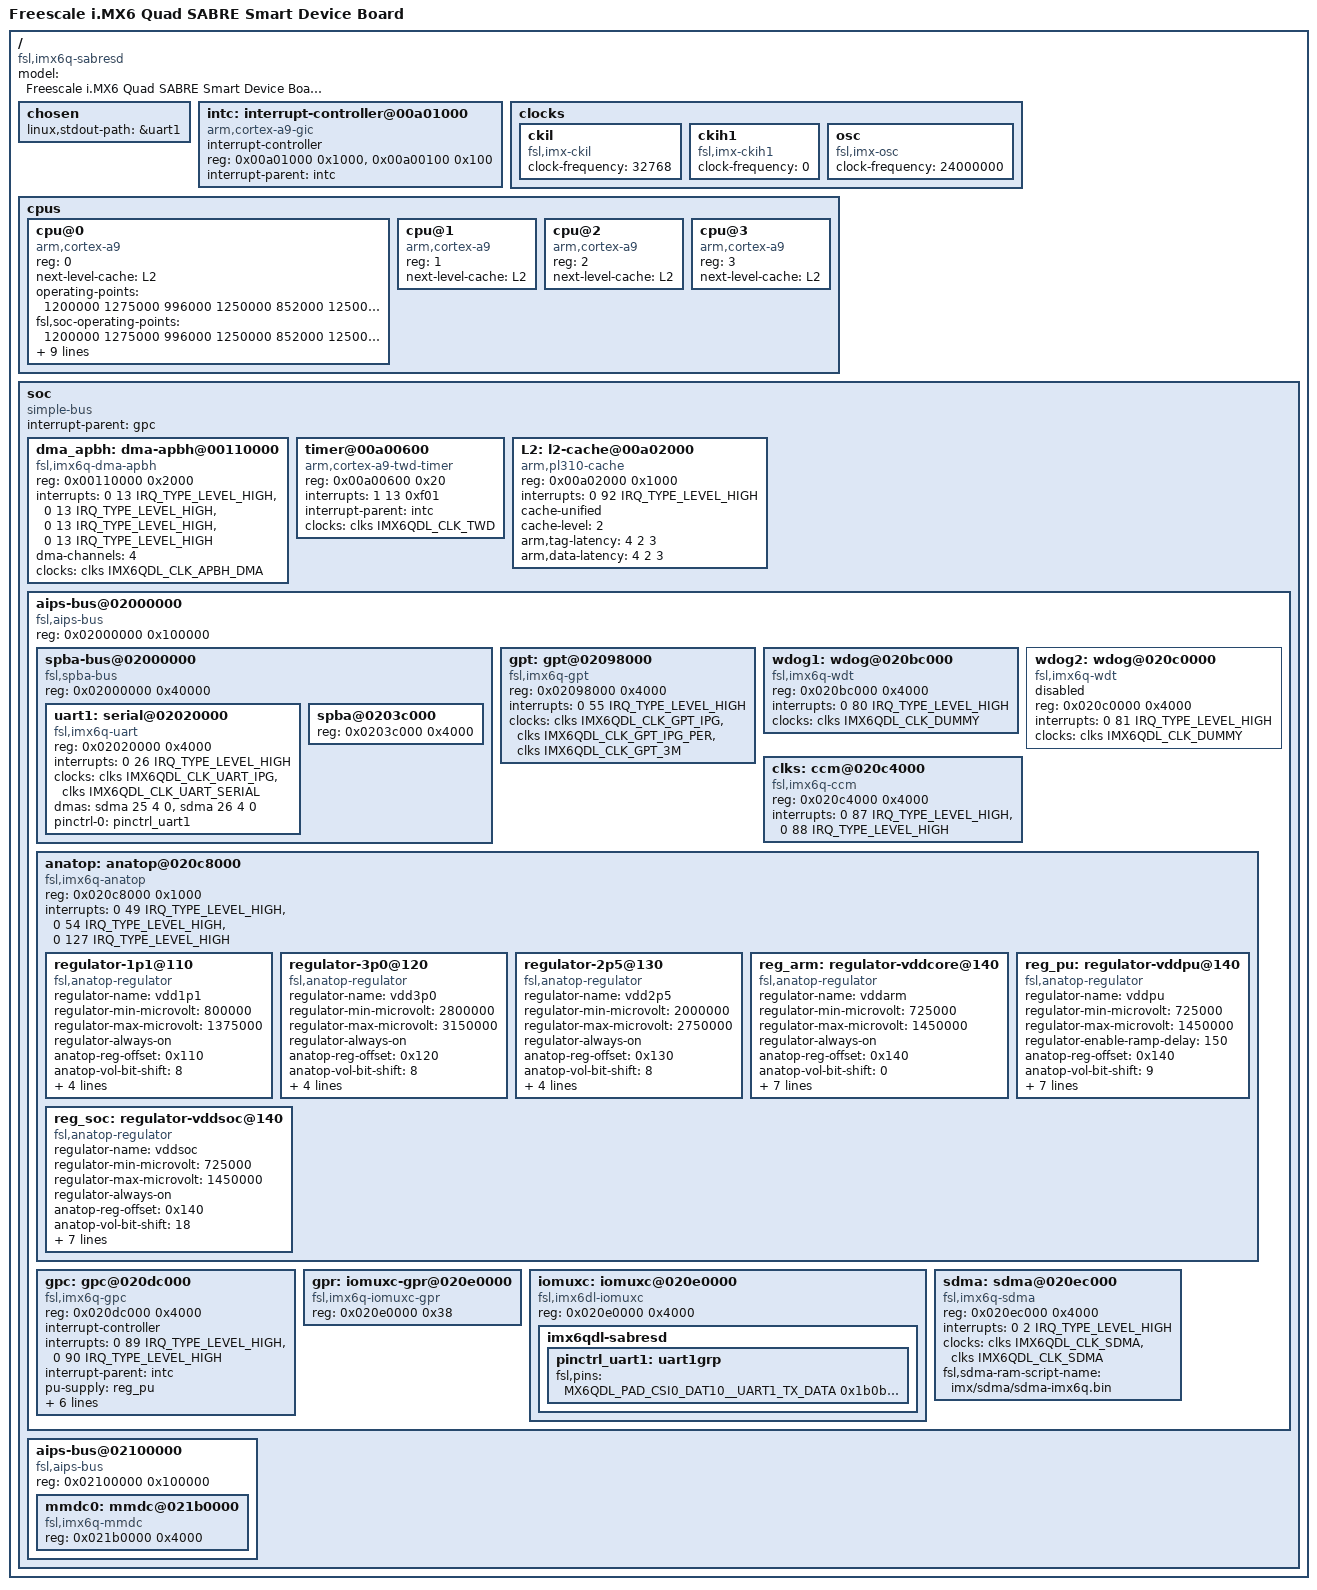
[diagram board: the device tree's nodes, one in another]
/*
* Copyright 2012 Freescale Semiconductor, Inc.
* Copyright 2011 Linaro Ltd.
*
* The code contained herein is licensed under the GNU General Public
* License. You may obtain a copy of the GNU General Public License
* Version 2 or later at the following locations:
*
* http://www.opensource.org/licenses/gpl-license.html
* http://www.gnu.org/copyleft/gpl.html
*/

/dts-v1/;

#include <dt-bindings/gpio/gpio.h>
#include <dt-bindings/input/input.h>
#include <dt-bindings/clock/imx6qdl-clock.h>
#include <dt-bindings/interrupt-controller/arm-gic.h>
#include <dt-bindings/interrupt-controller/irq.h>
#include <arm/imx6q-pinfunc.h>


#include "skeleton.dtsi"

/ {
	model = "Freescale i.MX6 Quad SABRE Smart Device Board";
	compatible = "fsl,imx6q-sabresd", "fsl,imx6q";

	chosen {
		linux,stdout-path = &uart1;
	};

	/* memory { */
	/* 	device_type = "memory"; */
	/* 	reg = <0x00900000 0x40000>; */
	/* }; */

	intc: interrupt-controller@00a01000 {
		compatible = "arm,cortex-a9-gic";
		#interrupt-cells = <3>;
		interrupt-controller;
		reg = <0x00a01000 0x1000>,
		<0x00a00100 0x100>;
		interrupt-parent = <&intc>;
	};

	clocks {
		#address-cells = <1>;
		#size-cells = <0>;

		ckil {
			compatible = "fsl,imx-ckil", "fixed-clock";
			#clock-cells = <0>;
			clock-frequency = <32768>;
		};

		ckih1 {
			compatible = "fsl,imx-ckih1", "fixed-clock";
			#clock-cells = <0>;
			clock-frequency = <0>;
		};

		osc {
			compatible = "fsl,imx-osc", "fixed-clock";
			#clock-cells = <0>;
			clock-frequency = <24000000>;
		};
	};

	cpus {
		#address-cells = <1>;
		#size-cells = <0>;

		cpu@0 {
			compatible = "arm,cortex-a9";
			device_type = "cpu";
			reg = <0>;
			next-level-cache = <&L2>;
			operating-points = <
			/* kHz    uV */
			1200000 1275000
			996000  1250000
			852000  1250000
			792000  1175000
			396000  975000
			>;
			fsl,soc-operating-points = <
			/* ARM kHz  SOC-PU uV */
			1200000 1275000
			996000	1250000
			852000	1250000
			792000	1175000
			396000	1175000
			>;
			clock-latency = <61036>; /* two CLK32 periods */
			clocks = <&clks IMX6QDL_CLK_ARM>,
			<&clks IMX6QDL_CLK_PLL2_PFD2_396M>,
			<&clks IMX6QDL_CLK_STEP>,
			<&clks IMX6QDL_CLK_PLL1_SW>,
			<&clks IMX6QDL_CLK_PLL1_SYS>;
			clock-names = "arm", "pll2_pfd2_396m", "step",
			"pll1_sw", "pll1_sys";
			arm-supply = <&reg_arm>;
			pu-supply = <&reg_pu>;
			soc-supply = <&reg_soc>;
		};

		cpu@1 {
			compatible = "arm,cortex-a9";
			device_type = "cpu";
			reg = <1>;
			next-level-cache = <&L2>;
		};

		cpu@2 {
			compatible = "arm,cortex-a9";
			device_type = "cpu";
			reg = <2>;
			next-level-cache = <&L2>;
		};

		cpu@3 {
			compatible = "arm,cortex-a9";
			device_type = "cpu";
			reg = <3>;
			next-level-cache = <&L2>;
		};
	};

	soc {
		#address-cells = <1>;
		#size-cells = <1>;
		compatible = "simple-bus";
		interrupt-parent = <&gpc>;
		ranges;

		dma_apbh: dma-apbh@00110000 {
			compatible = "fsl,imx6q-dma-apbh", "fsl,imx28-dma-apbh";
			reg = <0x00110000 0x2000>;
			interrupts = <0 13 IRQ_TYPE_LEVEL_HIGH>,
			<0 13 IRQ_TYPE_LEVEL_HIGH>,
			<0 13 IRQ_TYPE_LEVEL_HIGH>,
			<0 13 IRQ_TYPE_LEVEL_HIGH>;
			interrupt-names = "gpmi0", "gpmi1", "gpmi2", "gpmi3";
			#dma-cells = <1>;
			dma-channels = <4>;
			clocks = <&clks IMX6QDL_CLK_APBH_DMA>;
		};

		timer@00a00600 {
			compatible = "arm,cortex-a9-twd-timer";
			reg = <0x00a00600 0x20>;
			interrupts = <1 13 0xf01>;
			interrupt-parent = <&intc>;
			clocks = <&clks IMX6QDL_CLK_TWD>;
		};

		L2: l2-cache@00a02000 {
			compatible = "arm,pl310-cache";
			reg = <0x00a02000 0x1000>;
			interrupts = <0 92 IRQ_TYPE_LEVEL_HIGH>;
			cache-unified;
			cache-level = <2>;
			arm,tag-latency = <4 2 3>;
			arm,data-latency = <4 2 3>;
		};

		aips-bus@02000000 { /* AIPS1 */
			compatible = "fsl,aips-bus", "simple-bus";
			#address-cells = <1>;
			#size-cells = <1>;
			reg = <0x02000000 0x100000>;
			ranges;

			spba-bus@02000000 {
				compatible = "fsl,spba-bus", "simple-bus";
				#address-cells = <1>;
				#size-cells = <1>;
				reg = <0x02000000 0x40000>;
				ranges;

				uart1: serial@02020000 {
					compatible = "fsl,imx6q-uart", "fsl,imx21-uart";
					reg = <0x02020000 0x4000>;
					interrupts = <0 26 IRQ_TYPE_LEVEL_HIGH>;
					clocks = <&clks IMX6QDL_CLK_UART_IPG>,
					<&clks IMX6QDL_CLK_UART_SERIAL>;
					clock-names = "ipg", "per";
					dmas = <&sdma 25 4 0>, <&sdma 26 4 0>;
					dma-names = "rx", "tx";
					status = "disabled";
				};

				spba@0203c000 {
					reg = <0x0203c000 0x4000>;
				};
			};

			gpt: gpt@02098000 {
				compatible = "fsl,imx6q-gpt", "fsl,imx31-gpt";
				reg = <0x02098000 0x4000>;
				interrupts = <0 55 IRQ_TYPE_LEVEL_HIGH>;
				clocks = <&clks IMX6QDL_CLK_GPT_IPG>,
				<&clks IMX6QDL_CLK_GPT_IPG_PER>,
				<&clks IMX6QDL_CLK_GPT_3M>;
				clock-names = "ipg", "per", "osc_per";
			};

			wdog1: wdog@020bc000 {
				compatible = "fsl,imx6q-wdt", "fsl,imx21-wdt";
				reg = <0x020bc000 0x4000>;
				interrupts = <0 80 IRQ_TYPE_LEVEL_HIGH>;
				clocks = <&clks IMX6QDL_CLK_DUMMY>;
			};

			wdog2: wdog@020c0000 {
				compatible = "fsl,imx6q-wdt", "fsl,imx21-wdt";
				reg = <0x020c0000 0x4000>;
				interrupts = <0 81 IRQ_TYPE_LEVEL_HIGH>;
				clocks = <&clks IMX6QDL_CLK_DUMMY>;
				status = "disabled";
			};

			clks: ccm@020c4000 {
				compatible = "fsl,imx6q-ccm";
				reg = <0x020c4000 0x4000>;
				interrupts = <0 87 IRQ_TYPE_LEVEL_HIGH>,
				<0 88 IRQ_TYPE_LEVEL_HIGH>;
				#clock-cells = <1>;
			};

			anatop: anatop@020c8000 {
				compatible = "fsl,imx6q-anatop", "syscon", "simple-bus";
				reg = <0x020c8000 0x1000>;
				interrupts = <0 49 IRQ_TYPE_LEVEL_HIGH>,
				<0 54 IRQ_TYPE_LEVEL_HIGH>,
				<0 127 IRQ_TYPE_LEVEL_HIGH>;

				regulator-1p1@110 {
					compatible = "fsl,anatop-regulator";
					regulator-name = "vdd1p1";
					regulator-min-microvolt = <800000>;
					regulator-max-microvolt = <1375000>;
					regulator-always-on;
					anatop-reg-offset = <0x110>;
					anatop-vol-bit-shift = <8>;
					anatop-vol-bit-width = <5>;
					anatop-min-bit-val = <4>;
					anatop-min-voltage = <800000>;
					anatop-max-voltage = <1375000>;
				};

				regulator-3p0@120 {
					compatible = "fsl,anatop-regulator";
					regulator-name = "vdd3p0";
					regulator-min-microvolt = <2800000>;
					regulator-max-microvolt = <3150000>;
					regulator-always-on;
					anatop-reg-offset = <0x120>;
					anatop-vol-bit-shift = <8>;
					anatop-vol-bit-width = <5>;
					anatop-min-bit-val = <0>;
					anatop-min-voltage = <2625000>;
					anatop-max-voltage = <3400000>;
				};

				regulator-2p5@130 {
					compatible = "fsl,anatop-regulator";
					regulator-name = "vdd2p5";
					regulator-min-microvolt = <2000000>;
					regulator-max-microvolt = <2750000>;
					regulator-always-on;
					anatop-reg-offset = <0x130>;
					anatop-vol-bit-shift = <8>;
					anatop-vol-bit-width = <5>;
					anatop-min-bit-val = <0>;
					anatop-min-voltage = <2000000>;
					anatop-max-voltage = <2750000>;
				};

				reg_arm: regulator-vddcore@140 {
					compatible = "fsl,anatop-regulator";
					regulator-name = "vddarm";
					regulator-min-microvolt = <725000>;
					regulator-max-microvolt = <1450000>;
					regulator-always-on;
					anatop-reg-offset = <0x140>;
					anatop-vol-bit-shift = <0>;
					anatop-vol-bit-width = <5>;
					anatop-delay-reg-offset = <0x170>;
					anatop-delay-bit-shift = <24>;
					anatop-delay-bit-width = <2>;
					anatop-min-bit-val = <1>;
					anatop-min-voltage = <725000>;
					anatop-max-voltage = <1450000>;
				};

				reg_pu: regulator-vddpu@140 {
					compatible = "fsl,anatop-regulator";
					regulator-name = "vddpu";
					regulator-min-microvolt = <725000>;
					regulator-max-microvolt = <1450000>;
					regulator-enable-ramp-delay = <150>;
					anatop-reg-offset = <0x140>;
					anatop-vol-bit-shift = <9>;
					anatop-vol-bit-width = <5>;
					anatop-delay-reg-offset = <0x170>;
					anatop-delay-bit-shift = <26>;
					anatop-delay-bit-width = <2>;
					anatop-min-bit-val = <1>;
					anatop-min-voltage = <725000>;
					anatop-max-voltage = <1450000>;
				};

				reg_soc: regulator-vddsoc@140 {
					compatible = "fsl,anatop-regulator";
					regulator-name = "vddsoc";
					regulator-min-microvolt = <725000>;
					regulator-max-microvolt = <1450000>;
					regulator-always-on;
					anatop-reg-offset = <0x140>;
					anatop-vol-bit-shift = <18>;
					anatop-vol-bit-width = <5>;
					anatop-delay-reg-offset = <0x170>;
					anatop-delay-bit-shift = <28>;
					anatop-delay-bit-width = <2>;
					anatop-min-bit-val = <1>;
					anatop-min-voltage = <725000>;
					anatop-max-voltage = <1450000>;
				};
			};

			gpc: gpc@020dc000 {
				compatible = "fsl,imx6q-gpc";
				reg = <0x020dc000 0x4000>;
				interrupt-controller;
				#interrupt-cells = <3>;
				interrupts = <0 89 IRQ_TYPE_LEVEL_HIGH>,
				<0 90 IRQ_TYPE_LEVEL_HIGH>;
				interrupt-parent = <&intc>;
				pu-supply = <&reg_pu>;
				clocks = <&clks IMX6QDL_CLK_GPU3D_CORE>,
				<&clks IMX6QDL_CLK_GPU3D_SHADER>,
				<&clks IMX6QDL_CLK_GPU2D_CORE>,
				<&clks IMX6QDL_CLK_GPU2D_AXI>,
				<&clks IMX6QDL_CLK_OPENVG_AXI>,
				<&clks IMX6QDL_CLK_VPU_AXI>;
				#power-domain-cells = <1>;
			};

			gpr: iomuxc-gpr@020e0000 {
				compatible = "fsl,imx6q-iomuxc-gpr", "syscon";
				reg = <0x020e0000 0x38>;
			};

			iomuxc: iomuxc@020e0000 {
				compatible = "fsl,imx6dl-iomuxc", "fsl,imx6q-iomuxc";
				reg = <0x020e0000 0x4000>;
			};

			sdma: sdma@020ec000 {
				compatible = "fsl,imx6q-sdma", "fsl,imx35-sdma";
				reg = <0x020ec000 0x4000>;
				interrupts = <0 2 IRQ_TYPE_LEVEL_HIGH>;
				clocks = <&clks IMX6QDL_CLK_SDMA>,
				<&clks IMX6QDL_CLK_SDMA>;
				clock-names = "ipg", "ahb";
				#dma-cells = <3>;
				fsl,sdma-ram-script-name = "imx/sdma/sdma-imx6q.bin";
			};
		};

		aips-bus@02100000 { /* AIPS2 */
			compatible = "fsl,aips-bus", "simple-bus";
			#address-cells = <1>;
			#size-cells = <1>;
			reg = <0x02100000 0x100000>;
			ranges;

			mmdc0: mmdc@021b0000 { /* MMDC0 */
				compatible = "fsl,imx6q-mmdc";
				reg = <0x021b0000 0x4000>;
			};
		};
	};
};

&iomuxc {
	pinctrl-names = "default";

	imx6qdl-sabresd {
		pinctrl_uart1: uart1grp {
			fsl,pins = <
			MX6QDL_PAD_CSI0_DAT10__UART1_TX_DATA	0x1b0b1
			MX6QDL_PAD_CSI0_DAT11__UART1_RX_DATA	0x1b0b1
			>;
		};
	};
};

&uart1 {
	pinctrl-names = "default";
	pinctrl-0 = <&pinctrl_uart1>;
	status = "okay";
};
